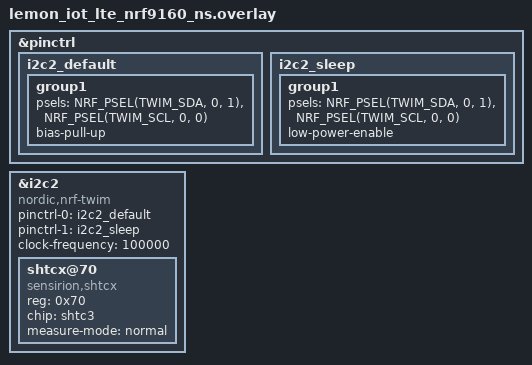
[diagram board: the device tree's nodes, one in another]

// DeviceTree overlay for Lemon IoT LTE nRF9160 Board
//
// Copyright (c) 2023 Aaron Mohtar & Co Pty Ltd
// SPDX-License-Identifier: Apache-2.0

&pinctrl {

	i2c2_default: i2c2_default {
		group1 {
			psels = <NRF_PSEL(TWIM_SDA, 0, 1)>,
					<NRF_PSEL(TWIM_SCL, 0, 0)>;
			bias-pull-up;
		};
	};

	i2c2_sleep: i2c2_sleep {
		group1 {
			psels = <NRF_PSEL(TWIM_SDA, 0, 1)>,
					<NRF_PSEL(TWIM_SCL, 0, 0)>;
			low-power-enable;
		};
	};
};

&i2c2 {
	compatible = "nordic,nrf-twim";
	status = "okay";
	pinctrl-0 = <&i2c2_default>;
	pinctrl-1 = <&i2c2_sleep>;
	pinctrl-names = "default", "sleep";
	clock-frequency = <100000>;
	shtcx@70 {
		compatible = "sensirion,shtcx";
		reg = <0x70>;
		chip = "shtc3";
		measure-mode = "normal";
	};
};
